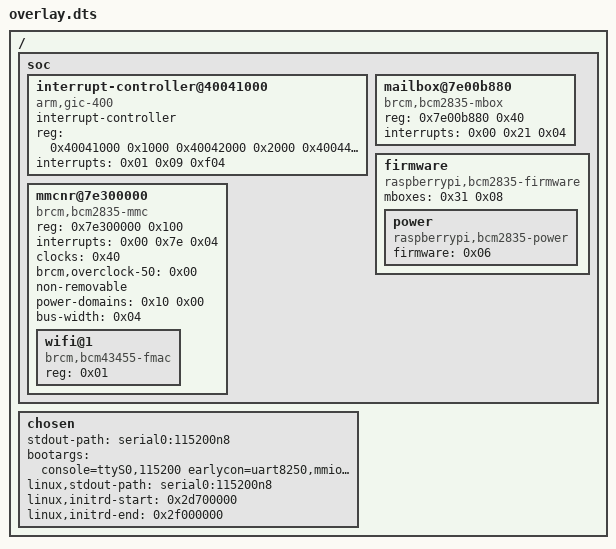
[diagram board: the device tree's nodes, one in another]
/ {
    soc {
        interrupt-controller@40041000 {
            interrupt-controller;
            #interrupt-cells = <0x03>;
            compatible = "arm,gic-400";
            reg = <0x40041000 0x1000 0x40042000 0x2000 0x40044000 0x2000 0x40046000 0x2000>;
            interrupts = <0x01 0x09 0xf04>;
            phandle = <0x01>;
        };

        mailbox@7e00b880 {
            compatible = "brcm,bcm2835-mbox";
            reg = <0x7e00b880 0x40>;
            interrupts = <0x00 0x21 0x04>;
            #mbox-cells = <0x01>;
            status = "okay";
            phandle = <0x31>;
        };

        firmware {
            compatible = "raspberrypi,bcm2835-firmware", "simple-bus";
            mboxes = <0x31 0x08>;
            status = "okay";
            phandle = <0x06>;

            power {
                compatible = "raspberrypi,bcm2835-power";
                firmware = <0x06>;
                #power-domain-cells = <0x01>;
                status = "okay";
                phandle = <0x10>;
            };
        };

        mmcnr@7e300000 {
            compatible = "brcm,bcm2835-mmc", "brcm,bcm2835-sdhci";
            reg = <0x7e300000 0x100>;
            interrupts = <0x00 0x7e 0x04>;
            clocks = <0x40>;
            brcm,overclock-50 = <0x00>;
            non-removable;
            status = "okay";
            power-domains = <0x10 0x00>;
            #address-cells = <0x01>;
            #size-cells = <0x00>;
            bus-width = <0x04>;

            wifi@1 {
                reg = <0x01>;
                compatible = "brcm,bcm43455-fmac", "brcm,bcm4329-fmac";
                status = "okay";
            };
        };
    };

    chosen {
        stdout-path = "serial0:115200n8";
        bootargs = "console=ttyS0,115200 earlycon=uart8250,mmio32,0xfe215040 debug loglevel=8";
        linux,stdout-path = "serial0:115200n8";
        linux,initrd-start = <0x2d700000>;
        linux,initrd-end = <0x2f000000>;
    };
};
